AUTOSAR XML (schema 4-2-2)
package /ComponentTypes
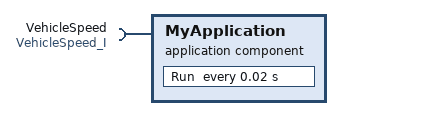
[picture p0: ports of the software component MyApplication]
  application sw component type MyApplication
    require port VehicleSpeed: nonqueued-receiver-com-spec{data-element=VehicleSpeed, filter=data-filter-type=ALWAYS, init-value=constant-reference=VehicleSpeed_IV}, required-interface=VehicleSpeed_I
    behavior MyApplication_InternalBehavior: port-api-option{enable-take-address=false, error-handling=NO-TRANSFORMER-ERROR-HANDLING, indirect-api=false, port=VehicleSpeed}
      timing event TMT_Run: start-on-event=Run, period=0.02
      runnable Run
        data-receive-point-by-arguments:
          access REC_VehicleSpeed_VehicleSpeed: accessed-variable=VehicleSpeed.VehicleSpeed
  swc implementation MyApplication_Implementation: behavior=MyApplication_InternalBehavior
